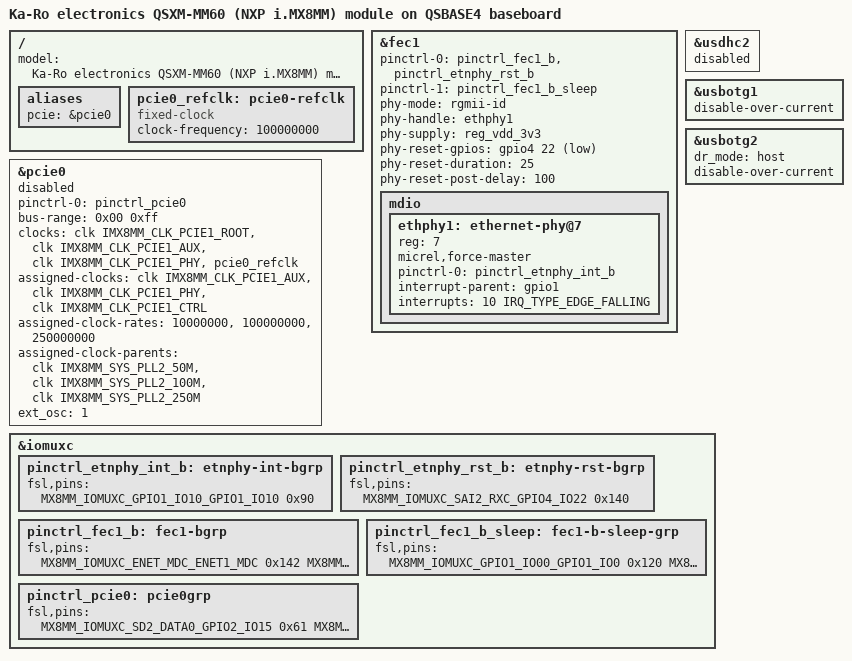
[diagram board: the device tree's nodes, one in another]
// SPDX-License-Identifier: (GPL-2.0 OR MIT)
/*
 * Copyright (C) 2019 Lothar Waßmann <LW@KARO-electronics.de>
 *
 */

/dts-v1/;

#include "imx8mm-qsxm-mm60.dts"

/ {
	model = "Ka-Ro electronics QSXM-MM60 (NXP i.MX8MM) module on QSBASE4 baseboard";

	aliases {
		pcie = &pcie0;
	};

	pcie0_refclk: pcie0-refclk {
		compatible = "fixed-clock";
		#clock-cells = <0>;
		clock-frequency = <100000000>;
	};
};

&fec1 {
	pinctrl-names = "default", "sleep";
	pinctrl-0 = <&pinctrl_fec1_b &pinctrl_etnphy_rst_b>;
	pinctrl-1 = <&pinctrl_fec1_b_sleep>;
	phy-mode = "rgmii-id";
	phy-handle = <&ethphy1>;
	phy-supply = <&reg_vdd_3v3>;
	phy-reset-gpios = <&gpio4 22 GPIO_ACTIVE_LOW>;
	phy-reset-duration = <25>;
	phy-reset-post-delay = <100>;
	status = "okay";

	mdio {
		#address-cells = <1>;
		#size-cells = <0>;

		ethphy1: ethernet-phy@7 {
			reg = <7>;
			micrel,force-master;
			pinctrl-names = "default";
			pinctrl-0 = <&pinctrl_etnphy_int_b>;
			interrupt-parent = <&gpio1>;
			interrupts = <10 IRQ_TYPE_EDGE_FALLING>;
		};
	};
};

&pcie0 {
	pinctrl-names = "default";
	pinctrl-0 = <&pinctrl_pcie0>;
	bus-range = <0x00 0xff>;
	clocks = <&clk IMX8MM_CLK_PCIE1_ROOT>,
		 <&clk IMX8MM_CLK_PCIE1_AUX>,
		 <&clk IMX8MM_CLK_PCIE1_PHY>,
		 <&pcie0_refclk>;
	clock-names = "pcie", "pcie_aux", "pcie_phy", "pcie_bus";
	assigned-clocks = <&clk IMX8MM_CLK_PCIE1_AUX>,
			  <&clk IMX8MM_CLK_PCIE1_PHY>,
			  <&clk IMX8MM_CLK_PCIE1_CTRL>;
	assigned-clock-rates = <10000000>, <100000000>, <250000000>;
	assigned-clock-parents = <&clk IMX8MM_SYS_PLL2_50M>,
				 <&clk IMX8MM_SYS_PLL2_100M>,
				 <&clk IMX8MM_SYS_PLL2_250M>;
	ext_osc = <1>;
	status = "disabled";
};

&usdhc2 {
	status = "disabled";
};

&usbotg1 {
	disable-over-current;
};

&usbotg2 {
	dr_mode = "host";
	disable-over-current;
	status = "okay";
};

&iomuxc {
	pinctrl_etnphy_int_b: etnphy-int-bgrp {
		fsl,pins = <
			    MX8MM_IOMUXC_GPIO1_IO10_GPIO1_IO10		0x90
		>;
	};

	pinctrl_etnphy_rst_b: etnphy-rst-bgrp {
		fsl,pins = <
			    MX8MM_IOMUXC_SAI2_RXC_GPIO4_IO22		0x140
		>;
	};

	pinctrl_fec1_b: fec1-bgrp {
		fsl,pins = <
			    MX8MM_IOMUXC_ENET_MDC_ENET1_MDC		0x142
			    MX8MM_IOMUXC_ENET_MDIO_ENET1_MDIO		0x142
			    MX8MM_IOMUXC_ENET_TXC_ENET1_RGMII_TXC	0x40000016
			    MX8MM_IOMUXC_ENET_TD0_ENET1_RGMII_TD0	0x016
			    MX8MM_IOMUXC_ENET_TD1_ENET1_RGMII_TD1	0x016
			    MX8MM_IOMUXC_ENET_TD2_ENET1_RGMII_TD2	0x016
			    MX8MM_IOMUXC_ENET_TD3_ENET1_RGMII_TD3	0x016
			    MX8MM_IOMUXC_ENET_TX_CTL_ENET1_RGMII_TX_CTL	0x016
			    MX8MM_IOMUXC_ENET_RD0_ENET1_RGMII_RD0	0x110 /* MODE0 */
			    MX8MM_IOMUXC_ENET_RD1_ENET1_RGMII_RD1	0x150 /* MODE1 */
			    MX8MM_IOMUXC_ENET_RD2_ENET1_RGMII_RD2	0x150 /* MODE2 */
			    MX8MM_IOMUXC_ENET_RD3_ENET1_RGMII_RD3	0x150 /* MODE3 */
			    MX8MM_IOMUXC_ENET_RXC_ENET1_RGMII_RXC	0x116 /* PHYAD2 */
			    MX8MM_IOMUXC_ENET_RX_CTL_ENET1_RGMII_RX_CTL	0x156 /* CLK125_EN */
			    MX8MM_IOMUXC_GPIO1_IO00_GPIO1_IO0		0x110 /* LED_MODE */
		>;
	};

	pinctrl_fec1_b_sleep: fec1-b-sleep-grp {
		fsl,pins = <
			    MX8MM_IOMUXC_GPIO1_IO00_GPIO1_IO0		0x120
			    MX8MM_IOMUXC_ENET_MDC_GPIO1_IO16		0x120
			    MX8MM_IOMUXC_ENET_MDIO_GPIO1_IO17		0x120
			    MX8MM_IOMUXC_ENET_TXC_GPIO1_IO23		0x40000120
			    MX8MM_IOMUXC_ENET_TD0_GPIO1_IO21		0x120
			    MX8MM_IOMUXC_ENET_TD1_GPIO1_IO20		0x120
			    MX8MM_IOMUXC_ENET_TD2_GPIO1_IO19		0x120
			    MX8MM_IOMUXC_ENET_TD3_GPIO1_IO18		0x120
			    MX8MM_IOMUXC_ENET_RD0_GPIO1_IO26		0x120
			    MX8MM_IOMUXC_ENET_RD1_GPIO1_IO27		0x120
			    MX8MM_IOMUXC_ENET_RD2_GPIO1_IO28		0x120
			    MX8MM_IOMUXC_ENET_RD3_GPIO1_IO29		0x120
			    MX8MM_IOMUXC_ENET_RXC_GPIO1_IO25		0x120
			    MX8MM_IOMUXC_ENET_RX_CTL_GPIO1_IO24		0x120
			    MX8MM_IOMUXC_ENET_TX_CTL_GPIO1_IO22		0x120
		>;
	};

	pinctrl_pcie0: pcie0grp {
		fsl,pins = <
			MX8MM_IOMUXC_SD2_DATA0_GPIO2_IO15	0x61 /* open drain, pull up */
			MX8MM_IOMUXC_SD2_CLK_GPIO2_IO13		0x41
			MX8MM_IOMUXC_GPIO1_IO14_GPIO1_IO14	0x41
			MX8MM_IOMUXC_SD2_WP_GPIO2_IO20		0x41
		>;
	};
};
